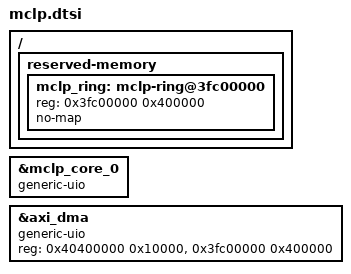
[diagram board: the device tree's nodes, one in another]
/*
 * mclp: user-space access through UIO (sw/linux/mclp).
 * mclp_core_0 is the packaged core in the block design; sdtgen writes its node (registers at 0x43c00000,
 * the interrupt through irq_concat) and this file hands it to UIO. The AXI DMA is handed to UIO as well,
 * with the reserved capture ring as its second map.
 * The driver binds with: modprobe uio_pdrv_genirq of_id=generic-uio (done by /etc/init.d/mclp).
 */
/ {
	reserved-memory {
		#address-cells = <1>;
		#size-cells = <1>;
		ranges;

		mclp_ring: mclp-ring@3fc00000 {
			reg = <0x3fc00000 0x400000>;       /* top 4 MB of the 1 GB DDR */
			no-map;
		};
	};
};

&mclp_core_0 {
	compatible = "generic-uio";
};

&axi_dma {
	compatible = "generic-uio";
	reg = <0x40400000 0x10000>, <0x3fc00000 0x400000>;   /* map 0: S2MM registers, map 1: capture ring */
};
